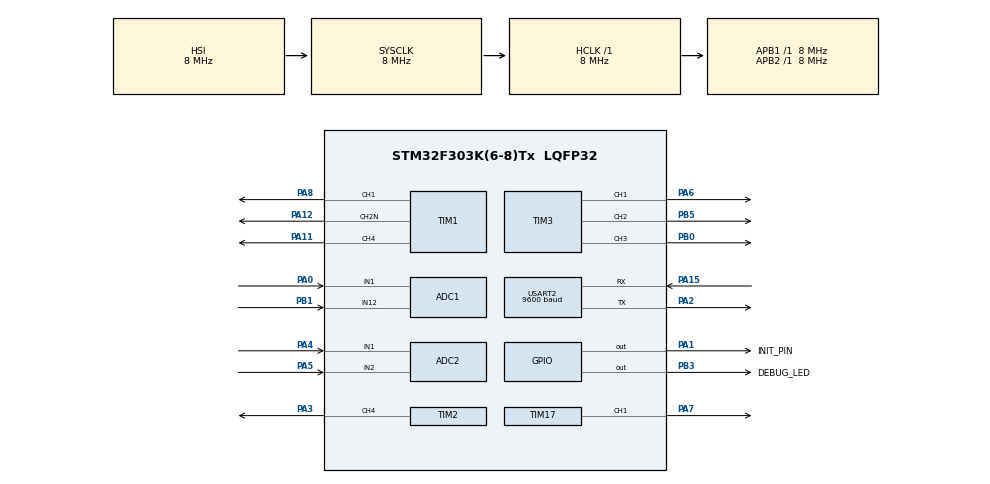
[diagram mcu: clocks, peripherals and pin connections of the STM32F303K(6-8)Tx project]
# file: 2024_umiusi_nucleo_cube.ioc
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ADC1.Channel-0\#ChannelRegularConversion=ADC_CHANNEL_1
ADC1.Channel-1\#ChannelRegularConversion=ADC_CHANNEL_12
ADC1.ClockPrescaler=ADC_CLOCK_ASYNC_DIV1
ADC1.ContinuousConvMode=ENABLE
ADC1.DMAContinuousRequests=ENABLE
ADC1.NbrOfConversion=2
ADC1.NbrOfConversionFlag=1
ADC1.Offset-0\#ChannelRegularConversion=0
ADC1.Offset-1\#ChannelRegularConversion=0
ADC1.OffsetNumber-0\#ChannelRegularConversion=ADC_OFFSET_NONE
ADC1.OffsetNumber-1\#ChannelRegularConversion=ADC_OFFSET_NONE
ADC1.Rank-0\#ChannelRegularConversion=1
ADC1.Rank-1\#ChannelRegularConversion=2
ADC1.SamplingTime-0\#ChannelRegularConversion=ADC_SAMPLETIME_61CYCLES_5
ADC1.SamplingTime-1\#ChannelRegularConversion=ADC_SAMPLETIME_61CYCLES_5
ADC1.SamplingTimeOPAMP-1\#ChannelRegularConversion=ADC_SAMPLETIME_7CYCLES_5
ADC1.SubFamily=STM32F303x8
ADC1.master=1
ADC2.Channel-0\#ChannelRegularConversion=ADC_CHANNEL_1
ADC2.NbrOfConversionFlag=1
ADC2.Offset-0\#ChannelRegularConversion=0
ADC2.OffsetNumber-0\#ChannelRegularConversion=ADC_OFFSET_NONE
ADC2.Rank-0\#ChannelRegularConversion=1
ADC2.SamplingTime-0\#ChannelRegularConversion=ADC_SAMPLETIME_1CYCLE_5
ADC2.SamplingTimeOPAMP-0\#ChannelRegularConversion=ADC_SAMPLETIME_4CYCLES_5
ADC2.SingleDiff-0\#ChannelRegularConversion=ADC_DIFFERENTIAL_ENDED
ADC2.SubFamily=STM32F303x8
Dma.ADC1.2.Direction=DMA_PERIPH_TO_MEMORY
Dma.ADC1.2.Instance=DMA1_Channel1
Dma.ADC1.2.MemDataAlignment=DMA_MDATAALIGN_HALFWORD
Dma.ADC1.2.MemInc=DMA_MINC_ENABLE
Dma.ADC1.2.Mode=DMA_NORMAL
Dma.ADC1.2.PeriphDataAlignment=DMA_PDATAALIGN_HALFWORD
Dma.ADC1.2.PeriphInc=DMA_PINC_DISABLE
Dma.ADC1.2.Priority=DMA_PRIORITY_LOW
Dma.Request0=USART2_TX
Dma.Request1=USART2_RX
Dma.Request2=ADC1
Dma.USART2_RX.1.Direction=DMA_PERIPH_TO_MEMORY
Dma.USART2_RX.1.Instance=DMA1_Channel6
Dma.USART2_RX.1.MemDataAlignment=DMA_MDATAALIGN_BYTE
Dma.USART2_RX.1.MemInc=DMA_MINC_ENABLE
Dma.USART2_RX.1.Mode=DMA_NORMAL
Dma.USART2_RX.1.PeriphDataAlignment=DMA_PDATAALIGN_BYTE
Dma.USART2_RX.1.PeriphInc=DMA_PINC_DISABLE
Dma.USART2_RX.1.Priority=DMA_PRIORITY_LOW
Dma.USART2_TX.0.Direction=DMA_MEMORY_TO_PERIPH
Dma.USART2_TX.0.Instance=DMA1_Channel7
Dma.USART2_TX.0.MemDataAlignment=DMA_MDATAALIGN_BYTE
Dma.USART2_TX.0.MemInc=DMA_MINC_ENABLE
Dma.USART2_TX.0.Mode=DMA_NORMAL
Dma.USART2_TX.0.PeriphDataAlignment=DMA_PDATAALIGN_BYTE
Dma.USART2_TX.0.PeriphInc=DMA_PINC_DISABLE
Dma.USART2_TX.0.Priority=DMA_PRIORITY_LOW
Mcu.Family=STM32F3
Mcu.Name=STM32F303K(6-8)Tx
Mcu.Package=LQFP32
NVIC.DMA1_Channel1_IRQn=true\:1\:0\:true\:false\:true\:false\:true\:true
NVIC.DMA1_Channel6_IRQn=true\:1\:0\:true\:false\:true\:false\:true\:true
NVIC.DMA1_Channel7_IRQn=true\:1\:0\:true\:false\:true\:false\:true\:true
NVIC.PriorityGroup=NVIC_PRIORITYGROUP_4
PA0.Mode=IN1-Single-Ended
PA0.Signal=ADC1_IN1
PA1.GPIO_Label=INIT_PIN
PA1.Signal=GPIO_Output
PA11.Signal=S_TIM1_CH4
PA12.Mode=PWM Generation2 CH2N
PA12.Signal=TIM1_CH2N
PA15.Mode=Asynchronous
PA15.Signal=USART2_RX
PA2.Mode=Asynchronous
PA2.Signal=USART2_TX
PA3.Signal=S_TIM2_CH4
PA4.Mode=IN1-Differential
PA4.Signal=ADC2_IN1
PA5.Mode=IN1-Differential
PA5.Signal=ADC2_IN2
PA6.Signal=S_TIM3_CH1
PA7.Signal=S_TIM17_CH1
PA8.Signal=S_TIM1_CH1
PB0.Signal=S_TIM3_CH3
PB1.Mode=IN12-Single-Ended
PB1.Signal=ADC1_IN12
PB3.GPIO_Label=DEBUG_LED
PB3.Signal=GPIO_Output
PB5.Signal=S_TIM3_CH2
ProjectManager.HeapSize=0x200
ProjectManager.StackSize=0x400
ProjectManager.TargetToolchain=STM32CubeIDE
RCC.AHBFreq_Value=8000000
RCC.APB1Freq_Value=8000000
RCC.APB2Freq_Value=8000000
RCC.CortexFreq_Value=8000000
RCC.HSE_VALUE=8000000
RCC.HSI_VALUE=8000000
RCC.PLLMUL=RCC_PLL_MUL4
RCC.SYSCLKFreq_VALUE=8000000
SH.S_TIM17_CH1.0=TIM17_CH1,PWM Generation1 CH1
SH.S_TIM1_CH1.0=TIM1_CH1,PWM Generation1 CH1
SH.S_TIM1_CH4.0=TIM1_CH4,PWM Generation4 CH4
SH.S_TIM2_CH4.0=TIM2_CH4,PWM Generation4 CH4
SH.S_TIM3_CH1.0=TIM3_CH1,PWM Generation1 CH1
SH.S_TIM3_CH2.0=TIM3_CH2,PWM Generation2 CH2
SH.S_TIM3_CH3.0=TIM3_CH3,PWM Generation3 CH3
TIM1.Channel-PWM\ Generation1\ CH1=TIM_CHANNEL_1
TIM1.Channel-PWM\ Generation2\ CH2N=TIM_CHANNEL_2
TIM1.Channel-PWM\ Generation4\ CH4=TIM_CHANNEL_4
TIM17.Channel=TIM_CHANNEL_1
TIM2.Channel-PWM\ Generation4\ CH4=TIM_CHANNEL_4
TIM3.Channel-PWM\ Generation1\ CH1=TIM_CHANNEL_1
TIM3.Channel-PWM\ Generation2\ CH2=TIM_CHANNEL_2
TIM3.Channel-PWM\ Generation3\ CH3=TIM_CHANNEL_3
USART2.BaudRate=9600
USART2.VirtualMode-Asynchronous=VM_ASYNC
VP_IWDG_VS_IWDG.Mode=IWDG_Activate
VP_TIM17_VS_ClockSourceINT.Mode=Enable_Timer
VP_TIM1_VS_ClockSourceINT.Mode=Internal
VP_TIM2_VS_ClockSourceINT.Mode=Internal
VP_TIM3_VS_ClockSourceINT.Mode=Internal
board=custom

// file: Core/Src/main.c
/* USER CODE BEGIN Header */
/**
 ******************************************************************************
 * @file           : main.c
 * @brief          : Main program body
 ******************************************************************************
 * @attention
 *
 * Copyright (c) 2024 STMicroelectronics.
 * All rights reserved.
 *
 * This software is licensed under terms that can be found in the LICENSE file
 * in the root directory of this software component.
 * If no LICENSE file comes with this software, it is provided AS-IS.
 *
 ******************************************************************************
 */
/* USER CODE END Header */
#include "main.h"

/* USER CODE BEGIN Includes */
#include "umiusi/machine.h"
#include "umiusi/signal.h"
/* USER CODE END Includes */

ADC_HandleTypeDef hadc1;
ADC_HandleTypeDef hadc2;
DMA_HandleTypeDef hdma_adc1;

IWDG_HandleTypeDef hiwdg;

TIM_HandleTypeDef htim1;
TIM_HandleTypeDef htim2;
TIM_HandleTypeDef htim3;
TIM_HandleTypeDef htim17;

UART_HandleTypeDef huart2;
DMA_HandleTypeDef hdma_usart2_tx;
DMA_HandleTypeDef hdma_usart2_rx;

void SystemClock_Config(void);
static void MX_GPIO_Init(void);
static void MX_DMA_Init(void);
static void MX_ADC1_Init(void);
static void MX_ADC2_Init(void);
static void MX_TIM1_Init(void);
static void MX_TIM2_Init(void);
static void MX_TIM3_Init(void);
static void MX_TIM17_Init(void);
static void MX_USART2_UART_Init(void);
static void MX_IWDG_Init(void);

int main(void) {

    /* MCU Configuration--------------------------------------------------------*/

    /* Reset of all peripherals, Initializes the Flash interface and the Systick. */
    HAL_Init();

    /* Configure the system clock */
    SystemClock_Config();

    /* Initialize all configured peripherals */
    MX_GPIO_Init();
    MX_DMA_Init();
    MX_ADC1_Init();
    MX_ADC2_Init();
    MX_TIM1_Init();
    MX_TIM2_Init();
    MX_TIM3_Init();
    MX_TIM17_Init();
    MX_USART2_UART_Init();
    MX_IWDG_Init();
    /* USER CODE BEGIN 2 */
    signal_init();
    struct Machine machine = machine_init();
    /* USER CODE END 2 */

    /* Infinite loop */
    /* USER CODE BEGIN WHILE */
    while (1) {
        struct Signal signal = next_signal();
        machine_handle_signal(&machine, &signal);
        /* USER CODE END WHILE */

    }
}

void SystemClock_Config(void) {
    RCC_OscInitTypeDef RCC_OscInitStruct = { 0 };
    RCC_ClkInitTypeDef RCC_ClkInitStruct = { 0 };
    RCC_PeriphCLKInitTypeDef PeriphClkInit = { 0 };

    /** Initializes the RCC Oscillators according to the specified parameters
     * in the RCC_OscInitTypeDef structure.
     */
    RCC_OscInitStruct.OscillatorType = RCC_OSCILLATORTYPE_HSI | RCC_OSCILLATORTYPE_LSI;
    RCC_OscInitStruct.HSIState = RCC_HSI_ON;
    RCC_OscInitStruct.HSICalibrationValue = RCC_HSICALIBRATION_DEFAULT;
    RCC_OscInitStruct.LSIState = RCC_LSI_ON;
    RCC_OscInitStruct.PLL.PLLState = RCC_PLL_ON;
    RCC_OscInitStruct.PLL.PLLSource = RCC_PLLSOURCE_HSI;
    RCC_OscInitStruct.PLL.PLLMUL = RCC_PLL_MUL4;
    if (HAL_RCC_OscConfig(&RCC_OscInitStruct) != HAL_OK) {
        Error_Handler();
    }

    /** Initializes the CPU, AHB and APB buses clocks
     */
    RCC_ClkInitStruct.ClockType = RCC_CLOCKTYPE_HCLK | RCC_CLOCKTYPE_SYSCLK
                                  | RCC_CLOCKTYPE_PCLK1 | RCC_CLOCKTYPE_PCLK2;
    RCC_ClkInitStruct.SYSCLKSource = RCC_SYSCLKSOURCE_HSI;
    RCC_ClkInitStruct.AHBCLKDivider = RCC_SYSCLK_DIV1;
    RCC_ClkInitStruct.APB1CLKDivider = RCC_HCLK_DIV1;
    RCC_ClkInitStruct.APB2CLKDivider = RCC_HCLK_DIV1;

    if (HAL_RCC_ClockConfig(&RCC_ClkInitStruct, FLASH_LATENCY_0) != HAL_OK) {
        Error_Handler();
    }
    PeriphClkInit.PeriphClockSelection = RCC_PERIPHCLK_TIM1 | RCC_PERIPHCLK_ADC12;
    PeriphClkInit.Adc12ClockSelection = RCC_ADC12PLLCLK_DIV1;
    PeriphClkInit.Tim1ClockSelection = RCC_TIM1CLK_HCLK;
    if (HAL_RCCEx_PeriphCLKConfig(&PeriphClkInit) != HAL_OK) {
        Error_Handler();
    }
}

static void MX_ADC1_Init(void) {

    ADC_MultiModeTypeDef multimode = { 0 };
    ADC_ChannelConfTypeDef sConfig = { 0 };

    /** Common config
     */
    hadc1.Instance = ADC1;
    hadc1.Init.ClockPrescaler = ADC_CLOCK_ASYNC_DIV1;
    hadc1.Init.Resolution = ADC_RESOLUTION_12B;
    hadc1.Init.ScanConvMode = ADC_SCAN_ENABLE;
    hadc1.Init.ContinuousConvMode = ENABLE;
    hadc1.Init.DiscontinuousConvMode = DISABLE;
    hadc1.Init.ExternalTrigConvEdge = ADC_EXTERNALTRIGCONVEDGE_NONE;
    hadc1.Init.ExternalTrigConv = ADC_SOFTWARE_START;
    hadc1.Init.DataAlign = ADC_DATAALIGN_RIGHT;
    hadc1.Init.NbrOfConversion = 2;
    hadc1.Init.DMAContinuousRequests = ENABLE;
    hadc1.Init.EOCSelection = ADC_EOC_SINGLE_CONV;
    hadc1.Init.LowPowerAutoWait = DISABLE;
    hadc1.Init.Overrun = ADC_OVR_DATA_OVERWRITTEN;
    if (HAL_ADC_Init(&hadc1) != HAL_OK) {
        Error_Handler();
    }

    /** Configure the ADC multi-mode
     */
    multimode.Mode = ADC_MODE_INDEPENDENT;
    if (HAL_ADCEx_MultiModeConfigChannel(&hadc1, &multimode) != HAL_OK) {
        Error_Handler();
    }

    /** Configure Regular Channel
     */
    sConfig.Channel = ADC_CHANNEL_1;
    sConfig.Rank = ADC_REGULAR_RANK_1;
    sConfig.SingleDiff = ADC_SINGLE_ENDED;
    sConfig.SamplingTime = ADC_SAMPLETIME_61CYCLES_5;
    sConfig.OffsetNumber = ADC_OFFSET_NONE;
    sConfig.Offset = 0;
    if (HAL_ADC_ConfigChannel(&hadc1, &sConfig) != HAL_OK) {
        Error_Handler();
    }

    /** Configure Regular Channel
     */
    sConfig.Channel = ADC_CHANNEL_12;
    sConfig.Rank = ADC_REGULAR_RANK_2;
    if (HAL_ADC_ConfigChannel(&hadc1, &sConfig) != HAL_OK) {
        Error_Handler();
    }
}

static void MX_ADC2_Init(void) {

    ADC_ChannelConfTypeDef sConfig = { 0 };

    /** Common config
     */
    hadc2.Instance = ADC2;
    hadc2.Init.ClockPrescaler = ADC_CLOCK_ASYNC_DIV1;
    hadc2.Init.Resolution = ADC_RESOLUTION_12B;
    hadc2.Init.ScanConvMode = ADC_SCAN_DISABLE;
    hadc2.Init.ContinuousConvMode = DISABLE;
    hadc2.Init.DiscontinuousConvMode = DISABLE;
    hadc2.Init.ExternalTrigConvEdge = ADC_EXTERNALTRIGCONVEDGE_NONE;
    hadc2.Init.ExternalTrigConv = ADC_SOFTWARE_START;
    hadc2.Init.DataAlign = ADC_DATAALIGN_RIGHT;
    hadc2.Init.NbrOfConversion = 1;
    hadc2.Init.DMAContinuousRequests = DISABLE;
    hadc2.Init.EOCSelection = ADC_EOC_SINGLE_CONV;
    hadc2.Init.LowPowerAutoWait = DISABLE;
    hadc2.Init.Overrun = ADC_OVR_DATA_OVERWRITTEN;
    if (HAL_ADC_Init(&hadc2) != HAL_OK) {
        Error_Handler();
    }

    /** Configure Regular Channel
     */
    sConfig.Channel = ADC_CHANNEL_1;
    sConfig.Rank = ADC_REGULAR_RANK_1;
    sConfig.SingleDiff = ADC_DIFFERENTIAL_ENDED;
    sConfig.SamplingTime = ADC_SAMPLETIME_1CYCLE_5;
    sConfig.OffsetNumber = ADC_OFFSET_NONE;
    sConfig.Offset = 0;
    if (HAL_ADC_ConfigChannel(&hadc2, &sConfig) != HAL_OK) {
        Error_Handler();
    }
}

static void MX_IWDG_Init(void) {

    hiwdg.Instance = IWDG;
    hiwdg.Init.Prescaler = IWDG_PRESCALER_4;
    hiwdg.Init.Window = 4095;
    hiwdg.Init.Reload = 4095;
    if (HAL_IWDG_Init(&hiwdg) != HAL_OK) {
        Error_Handler();
    }
}

static void MX_TIM1_Init(void) {

    TIM_ClockConfigTypeDef sClockSourceConfig = { 0 };
    TIM_MasterConfigTypeDef sMasterConfig = { 0 };
    TIM_OC_InitTypeDef sConfigOC = { 0 };
    TIM_BreakDeadTimeConfigTypeDef sBreakDeadTimeConfig = { 0 };

    htim1.Instance = TIM1;
    htim1.Init.Prescaler = 0;
    htim1.Init.CounterMode = TIM_COUNTERMODE_UP;
    htim1.Init.Period = 65535;
    htim1.Init.ClockDivision = TIM_CLOCKDIVISION_DIV1;
    htim1.Init.RepetitionCounter = 0;
    htim1.Init.AutoReloadPreload = TIM_AUTORELOAD_PRELOAD_DISABLE;
    if (HAL_TIM_Base_Init(&htim1) != HAL_OK) {
        Error_Handler();
    }
    sClockSourceConfig.ClockSource = TIM_CLOCKSOURCE_INTERNAL;
    if (HAL_TIM_ConfigClockSource(&htim1, &sClockSourceConfig) != HAL_OK) {
        Error_Handler();
    }
    if (HAL_TIM_PWM_Init(&htim1) != HAL_OK) {
        Error_Handler();
    }
    sMasterConfig.MasterOutputTrigger = TIM_TRGO_RESET;
    sMasterConfig.MasterOutputTrigger2 = TIM_TRGO2_RESET;
    sMasterConfig.MasterSlaveMode = TIM_MASTERSLAVEMODE_DISABLE;
    if (HAL_TIMEx_MasterConfigSynchronization(&htim1, &sMasterConfig) != HAL_OK) {
        Error_Handler();
    }
    sConfigOC.OCMode = TIM_OCMODE_PWM1;
    sConfigOC.Pulse = 0;
    sConfigOC.OCPolarity = TIM_OCPOLARITY_HIGH;
    sConfigOC.OCNPolarity = TIM_OCNPOLARITY_HIGH;
    sConfigOC.OCFastMode = TIM_OCFAST_DISABLE;
    sConfigOC.OCIdleState = TIM_OCIDLESTATE_RESET;
    sConfigOC.OCNIdleState = TIM_OCNIDLESTATE_RESET;
    if (HAL_TIM_PWM_ConfigChannel(&htim1, &sConfigOC, TIM_CHANNEL_1) != HAL_OK) {
        Error_Handler();
    }
    if (HAL_TIM_PWM_ConfigChannel(&htim1, &sConfigOC, TIM_CHANNEL_2) != HAL_OK) {
        Error_Handler();
    }
    if (HAL_TIM_PWM_ConfigChannel(&htim1, &sConfigOC, TIM_CHANNEL_4) != HAL_OK) {
        Error_Handler();
    }
    sBreakDeadTimeConfig.OffStateRunMode = TIM_OSSR_DISABLE;
    sBreakDeadTimeConfig.OffStateIDLEMode = TIM_OSSI_DISABLE;
    sBreakDeadTimeConfig.LockLevel = TIM_LOCKLEVEL_OFF;
    sBreakDeadTimeConfig.DeadTime = 0;
    sBreakDeadTimeConfig.BreakState = TIM_BREAK_DISABLE;
    sBreakDeadTimeConfig.BreakPolarity = TIM_BREAKPOLARITY_HIGH;
    sBreakDeadTimeConfig.BreakFilter = 0;
    sBreakDeadTimeConfig.Break2State = TIM_BREAK2_DISABLE;
    sBreakDeadTimeConfig.Break2Polarity = TIM_BREAK2POLARITY_HIGH;
    sBreakDeadTimeConfig.Break2Filter = 0;
    sBreakDeadTimeConfig.AutomaticOutput = TIM_AUTOMATICOUTPUT_DISABLE;
    if (HAL_TIMEx_ConfigBreakDeadTime(&htim1, &sBreakDeadTimeConfig) != HAL_OK) {
        Error_Handler();
    }
    HAL_TIM_MspPostInit(&htim1);
}

static void MX_TIM2_Init(void) {

    TIM_ClockConfigTypeDef sClockSourceConfig = { 0 };
    TIM_MasterConfigTypeDef sMasterConfig = { 0 };
    TIM_OC_InitTypeDef sConfigOC = { 0 };

    htim2.Instance = TIM2;
    htim2.Init.Prescaler = 0;
    htim2.Init.CounterMode = TIM_COUNTERMODE_UP;
    htim2.Init.Period = 4294967295;
    htim2.Init.ClockDivision = TIM_CLOCKDIVISION_DIV1;
    htim2.Init.AutoReloadPreload = TIM_AUTORELOAD_PRELOAD_DISABLE;
    if (HAL_TIM_Base_Init(&htim2) != HAL_OK) {
        Error_Handler();
    }
    sClockSourceConfig.ClockSource = TIM_CLOCKSOURCE_INTERNAL;
    if (HAL_TIM_ConfigClockSource(&htim2, &sClockSourceConfig) != HAL_OK) {
        Error_Handler();
    }
    if (HAL_TIM_PWM_Init(&htim2) != HAL_OK) {
        Error_Handler();
    }
    sMasterConfig.MasterOutputTrigger = TIM_TRGO_RESET;
    sMasterConfig.MasterSlaveMode = TIM_MASTERSLAVEMODE_DISABLE;
    if (HAL_TIMEx_MasterConfigSynchronization(&htim2, &sMasterConfig) != HAL_OK) {
        Error_Handler();
    }
    sConfigOC.OCMode = TIM_OCMODE_PWM1;
    sConfigOC.Pulse = 0;
    sConfigOC.OCPolarity = TIM_OCPOLARITY_HIGH;
    sConfigOC.OCFastMode = TIM_OCFAST_DISABLE;
    if (HAL_TIM_PWM_ConfigChannel(&htim2, &sConfigOC, TIM_CHANNEL_4) != HAL_OK) {
        Error_Handler();
    }
    HAL_TIM_MspPostInit(&htim2);
}

static void MX_TIM3_Init(void) {

    TIM_ClockConfigTypeDef sClockSourceConfig = { 0 };
    TIM_MasterConfigTypeDef sMasterConfig = { 0 };
    TIM_OC_InitTypeDef sConfigOC = { 0 };

    htim3.Instance = TIM3;
    htim3.Init.Prescaler = 0;
    htim3.Init.CounterMode = TIM_COUNTERMODE_UP;
    htim3.Init.Period = 65535;
    htim3.Init.ClockDivision = TIM_CLOCKDIVISION_DIV1;
    htim3.Init.AutoReloadPreload = TIM_AUTORELOAD_PRELOAD_DISABLE;
    if (HAL_TIM_Base_Init(&htim3) != HAL_OK) {
        Error_Handler();
    }
    sClockSourceConfig.ClockSource = TIM_CLOCKSOURCE_INTERNAL;
    if (HAL_TIM_ConfigClockSource(&htim3, &sClockSourceConfig) != HAL_OK) {
        Error_Handler();
    }
    if (HAL_TIM_PWM_Init(&htim3) != HAL_OK) {
        Error_Handler();
    }
    sMasterConfig.MasterOutputTrigger = TIM_TRGO_RESET;
    sMasterConfig.MasterSlaveMode = TIM_MASTERSLAVEMODE_DISABLE;
    if (HAL_TIMEx_MasterConfigSynchronization(&htim3, &sMasterConfig) != HAL_OK) {
        Error_Handler();
    }
    sConfigOC.OCMode = TIM_OCMODE_PWM1;
    sConfigOC.Pulse = 0;
    sConfigOC.OCPolarity = TIM_OCPOLARITY_HIGH;
    sConfigOC.OCFastMode = TIM_OCFAST_DISABLE;
    if (HAL_TIM_PWM_ConfigChannel(&htim3, &sConfigOC, TIM_CHANNEL_1) != HAL_OK) {
        Error_Handler();
    }
    if (HAL_TIM_PWM_ConfigChannel(&htim3, &sConfigOC, TIM_CHANNEL_2) != HAL_OK) {
        Error_Handler();
    }
    if (HAL_TIM_PWM_ConfigChannel(&htim3, &sConfigOC, TIM_CHANNEL_3) != HAL_OK) {
        Error_Handler();
    }
    HAL_TIM_MspPostInit(&htim3);
}

static void MX_TIM17_Init(void) {

    TIM_OC_InitTypeDef sConfigOC = { 0 };
    TIM_BreakDeadTimeConfigTypeDef sBreakDeadTimeConfig = { 0 };

    htim17.Instance = TIM17;
    htim17.Init.Prescaler = 0;
    htim17.Init.CounterMode = TIM_COUNTERMODE_UP;
    htim17.Init.Period = 65535;
    htim17.Init.ClockDivision = TIM_CLOCKDIVISION_DIV1;
    htim17.Init.RepetitionCounter = 0;
    htim17.Init.AutoReloadPreload = TIM_AUTORELOAD_PRELOAD_DISABLE;
    if (HAL_TIM_Base_Init(&htim17) != HAL_OK) {
        Error_Handler();
    }
    if (HAL_TIM_PWM_Init(&htim17) != HAL_OK) {
        Error_Handler();
    }
    sConfigOC.OCMode = TIM_OCMODE_PWM1;
    sConfigOC.Pulse = 0;
    sConfigOC.OCPolarity = TIM_OCPOLARITY_HIGH;
    sConfigOC.OCNPolarity = TIM_OCNPOLARITY_HIGH;
    sConfigOC.OCFastMode = TIM_OCFAST_DISABLE;
    sConfigOC.OCIdleState = TIM_OCIDLESTATE_RESET;
    sConfigOC.OCNIdleState = TIM_OCNIDLESTATE_RESET;
    if (HAL_TIM_PWM_ConfigChannel(&htim17, &sConfigOC, TIM_CHANNEL_1) != HAL_OK) {
        Error_Handler();
    }
    sBreakDeadTimeConfig.OffStateRunMode = TIM_OSSR_DISABLE;
    sBreakDeadTimeConfig.OffStateIDLEMode = TIM_OSSI_DISABLE;
    sBreakDeadTimeConfig.LockLevel = TIM_LOCKLEVEL_OFF;
    sBreakDeadTimeConfig.DeadTime = 0;
    sBreakDeadTimeConfig.BreakState = TIM_BREAK_DISABLE;
    sBreakDeadTimeConfig.BreakPolarity = TIM_BREAKPOLARITY_HIGH;
    sBreakDeadTimeConfig.BreakFilter = 0;
    sBreakDeadTimeConfig.AutomaticOutput = TIM_AUTOMATICOUTPUT_DISABLE;
    if (HAL_TIMEx_ConfigBreakDeadTime(&htim17, &sBreakDeadTimeConfig) != HAL_OK) {
        Error_Handler();
    }
    HAL_TIM_MspPostInit(&htim17);
}

static void MX_USART2_UART_Init(void) {

    huart2.Instance = USART2;
    huart2.Init.BaudRate = 9600;
    huart2.Init.WordLength = UART_WORDLENGTH_8B;
    huart2.Init.StopBits = UART_STOPBITS_1;
    huart2.Init.Parity = UART_PARITY_NONE;
    huart2.Init.Mode = UART_MODE_TX_RX;
    huart2.Init.HwFlowCtl = UART_HWCONTROL_NONE;
    huart2.Init.OverSampling = UART_OVERSAMPLING_16;
    huart2.Init.OneBitSampling = UART_ONE_BIT_SAMPLE_DISABLE;
    huart2.AdvancedInit.AdvFeatureInit = UART_ADVFEATURE_NO_INIT;
    if (HAL_UART_Init(&huart2) != HAL_OK) {
        Error_Handler();
    }
}

static void MX_DMA_Init(void) {
    /* DMA controller clock enable */
    __HAL_RCC_DMA1_CLK_ENABLE();

    /* DMA interrupt init */
    /* DMA1_Channel1_IRQn interrupt configuration */
    HAL_NVIC_SetPriority(DMA1_Channel1_IRQn, 1, 0);
    HAL_NVIC_EnableIRQ(DMA1_Channel1_IRQn);
    /* DMA1_Channel6_IRQn interrupt configuration */
    HAL_NVIC_SetPriority(DMA1_Channel6_IRQn, 1, 0);
    HAL_NVIC_EnableIRQ(DMA1_Channel6_IRQn);
    /* DMA1_Channel7_IRQn interrupt configuration */
    HAL_NVIC_SetPriority(DMA1_Channel7_IRQn, 1, 0);
    HAL_NVIC_EnableIRQ(DMA1_Channel7_IRQn);
}

static void MX_GPIO_Init(void) {
    GPIO_InitTypeDef GPIO_InitStruct = { 0 };

    /* GPIO Ports Clock Enable */
    __HAL_RCC_GPIOA_CLK_ENABLE();
    __HAL_RCC_GPIOB_CLK_ENABLE();

    /*Configure GPIO pin Output Level */
    HAL_GPIO_WritePin(INIT_PIN_GPIO_Port, INIT_PIN_Pin, GPIO_PIN_RESET);

    /*Configure GPIO pin Output Level */
    HAL_GPIO_WritePin(DEBUG_LED_GPIO_Port, DEBUG_LED_Pin, GPIO_PIN_RESET);

    /*Configure GPIO pin : INIT_PIN_Pin */
    GPIO_InitStruct.Pin = INIT_PIN_Pin;
    GPIO_InitStruct.Mode = GPIO_MODE_OUTPUT_PP;
    GPIO_InitStruct.Pull = GPIO_NOPULL;
    GPIO_InitStruct.Speed = GPIO_SPEED_FREQ_LOW;
    HAL_GPIO_Init(INIT_PIN_GPIO_Port, &GPIO_InitStruct);

    /*Configure GPIO pin : DEBUG_LED_Pin */
    GPIO_InitStruct.Pin = DEBUG_LED_Pin;
    GPIO_InitStruct.Mode = GPIO_MODE_OUTPUT_PP;
    GPIO_InitStruct.Pull = GPIO_NOPULL;
    GPIO_InitStruct.Speed = GPIO_SPEED_FREQ_LOW;
    HAL_GPIO_Init(DEBUG_LED_GPIO_Port, &GPIO_InitStruct);

}

void Error_Handler(void) {
    __disable_irq();
    while (1) {
    }
}
